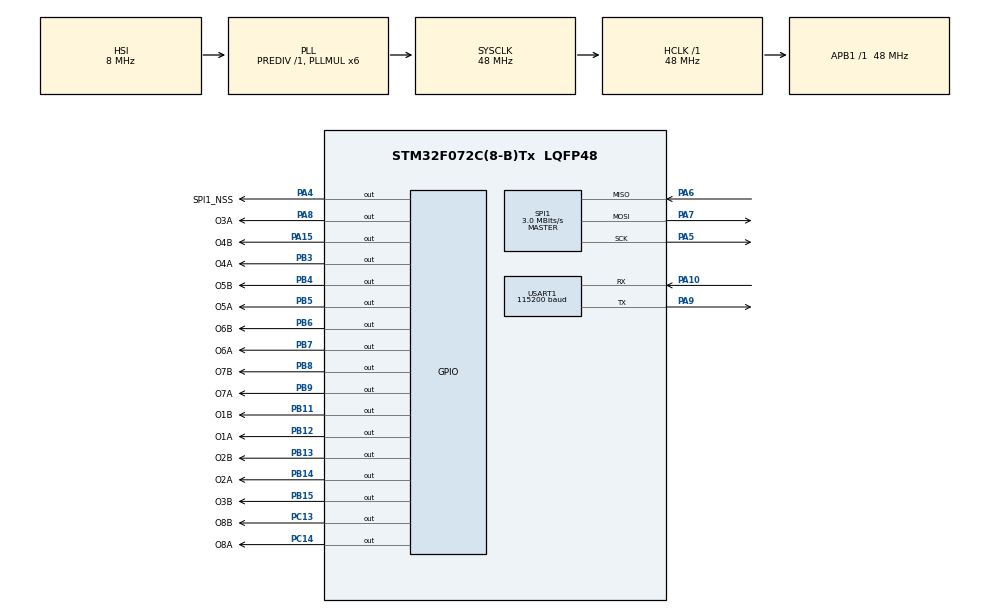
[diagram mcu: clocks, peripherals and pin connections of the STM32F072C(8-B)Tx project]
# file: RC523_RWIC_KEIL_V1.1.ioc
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Mcu.Family=STM32F0
Mcu.Name=STM32F072C(8-B)Tx
Mcu.Package=LQFP48
PA10.Mode=Asynchronous
PA10.Signal=USART1_RX
PA13.Mode=Serial_Wire
PA13.Signal=SYS_SWDIO
PA14.Mode=Serial_Wire
PA14.Signal=SYS_SWCLK
PA15.GPIO_Label=O4B
PA15.GPIO_Speed=GPIO_SPEED_FREQ_HIGH
PA15.PinState=GPIO_PIN_SET
PA15.Signal=GPIO_Output
PA4.GPIO_Label=SPI1_NSS
PA4.GPIO_Speed=GPIO_SPEED_FREQ_HIGH
PA4.PinState=GPIO_PIN_SET
PA4.Signal=GPIO_Output
PA5.Mode=Full_Duplex_Master
PA5.Signal=SPI1_SCK
PA6.Mode=Full_Duplex_Master
PA6.Signal=SPI1_MISO
PA7.Mode=Full_Duplex_Master
PA7.Signal=SPI1_MOSI
PA8.GPIO_Label=O3A
PA8.GPIO_Speed=GPIO_SPEED_FREQ_HIGH
PA8.PinState=GPIO_PIN_RESET
PA8.Signal=GPIO_Output
PA9.Mode=Asynchronous
PA9.Signal=USART1_TX
PB11.GPIO_Label=O1B
PB11.GPIO_Speed=GPIO_SPEED_FREQ_HIGH
PB11.PinState=GPIO_PIN_SET
PB11.Signal=GPIO_Output
PB12.GPIO_Label=O1A
PB12.GPIO_Speed=GPIO_SPEED_FREQ_HIGH
PB12.PinState=GPIO_PIN_RESET
PB12.Signal=GPIO_Output
PB13.GPIO_Label=O2B
PB13.GPIO_Speed=GPIO_SPEED_FREQ_HIGH
PB13.PinState=GPIO_PIN_SET
PB13.Signal=GPIO_Output
PB14.GPIO_Label=O2A
PB14.GPIO_Speed=GPIO_SPEED_FREQ_HIGH
PB14.PinState=GPIO_PIN_RESET
PB14.Signal=GPIO_Output
PB15.GPIO_Label=O3B
PB15.GPIO_Speed=GPIO_SPEED_FREQ_HIGH
PB15.PinState=GPIO_PIN_SET
PB15.Signal=GPIO_Output
PB3.GPIO_Label=O4A
PB3.GPIO_Speed=GPIO_SPEED_FREQ_HIGH
PB3.PinState=GPIO_PIN_RESET
PB3.Signal=GPIO_Output
PB4.GPIO_Label=O5B
PB4.GPIO_Speed=GPIO_SPEED_FREQ_HIGH
PB4.PinState=GPIO_PIN_SET
PB4.Signal=GPIO_Output
PB5.GPIO_Label=O5A
PB5.GPIO_Speed=GPIO_SPEED_FREQ_HIGH
PB5.Signal=GPIO_Output
PB6.GPIO_Label=O6B
PB6.GPIO_Speed=GPIO_SPEED_FREQ_HIGH
PB6.PinState=GPIO_PIN_SET
PB6.Signal=GPIO_Output
PB7.GPIO_Label=O6A
PB7.GPIO_Speed=GPIO_SPEED_FREQ_HIGH
PB7.PinState=GPIO_PIN_RESET
PB7.Signal=GPIO_Output
PB8.GPIO_Label=O7B
PB8.GPIO_Speed=GPIO_SPEED_FREQ_HIGH
PB8.PinState=GPIO_PIN_SET
PB8.Signal=GPIO_Output
PB9.GPIO_Label=O7A
PB9.GPIO_Speed=GPIO_SPEED_FREQ_HIGH
PB9.Signal=GPIO_Output
PC13.GPIO_Label=O8B
PC13.PinState=GPIO_PIN_SET
PC13.Signal=GPIO_Output
PC14-OSC32_IN.GPIO_Label=O8A
PC14-OSC32_IN.PinState=GPIO_PIN_RESET
PC14-OSC32_IN.Signal=GPIO_Output
PF0-OSC_IN.Mode=HSE-External-Oscillator
PF0-OSC_IN.Signal=RCC_OSC_IN
PF1-OSC_OUT.Mode=HSE-External-Oscillator
PF1-OSC_OUT.Signal=RCC_OSC_OUT
ProjectManager.HeapSize=0x200
ProjectManager.StackSize=0x400
ProjectManager.TargetToolchain=MDK-ARM V5.32
RCC.AHBFreq_Value=48000000
RCC.APB1Freq_Value=48000000
RCC.APB1TimFreq_Value=48000000
RCC.HCLKFreq_Value=48000000
RCC.PLLMUL=RCC_PLL_MUL6
RCC.SYSCLKFreq_VALUE=48000000
RCC.SYSCLKSource=RCC_SYSCLKSOURCE_PLLCLK
SPI1.BaudRatePrescaler=SPI_BAUDRATEPRESCALER_16
SPI1.CalculateBaudRate=3.0 MBits/s
SPI1.DataSize=SPI_DATASIZE_8BIT
SPI1.Direction=SPI_DIRECTION_2LINES
SPI1.Mode=SPI_MODE_MASTER
SPI1.VirtualType=VM_MASTER
USART1.BaudRate=115200
USART1.VirtualMode-Asynchronous=VM_ASYNC
board=custom

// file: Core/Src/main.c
/* USER CODE BEGIN Header */
/**
  ******************************************************************************
  * @file           : main.c
  * @brief          : Main program body
  ******************************************************************************
  * @attention
  *
  * Copyright (c) 2024 STMicroelectronics.
  * All rights reserved.
  *
  * This software is licensed under terms that can be found in the LICENSE file
  * in the root directory of this software component.
  * If no LICENSE file comes with this software, it is provided AS-IS.
  *
  ******************************************************************************
  */
/* USER CODE END Header */
#include "main.h"
#include "spi.h"
#include "usart.h"
#include "gpio.h"

/* USER CODE BEGIN Includes */
#include "RC523.h"
/* USER CODE END Includes */

void SystemClock_Config(void);

int main(void)
{

  /* MCU Configuration--------------------------------------------------------*/

  /* Reset of all peripherals, Initializes the Flash interface and the Systick. */
  HAL_Init();

  /* Configure the system clock */
  SystemClock_Config();

  /* Initialize all configured peripherals */
  MX_GPIO_Init();
  MX_SPI1_Init();
  MX_USART1_UART_Init();
  /* USER CODE BEGIN 2 */
  RC523_Init();
  /* USER CODE END 2 */

  /* Infinite loop */
  /* USER CODE BEGIN WHILE */
  while (1)
  {
		ScanChannlx();
		//HAL_Delay(3000);
		//HAL_Delay(1000);
    /* USER CODE END WHILE */

  }
}

void SystemClock_Config(void)
{
  RCC_OscInitTypeDef RCC_OscInitStruct = {0};
  RCC_ClkInitTypeDef RCC_ClkInitStruct = {0};
  RCC_PeriphCLKInitTypeDef PeriphClkInit = {0};

  /** Initializes the RCC Oscillators according to the specified parameters
  * in the RCC_OscInitTypeDef structure.
  */
  RCC_OscInitStruct.OscillatorType = RCC_OSCILLATORTYPE_HSI;
  RCC_OscInitStruct.HSIState = RCC_HSI_ON;
  RCC_OscInitStruct.HSICalibrationValue = RCC_HSICALIBRATION_DEFAULT;
  RCC_OscInitStruct.PLL.PLLState = RCC_PLL_ON;
  RCC_OscInitStruct.PLL.PLLSource = RCC_PLLSOURCE_HSI;
  RCC_OscInitStruct.PLL.PLLMUL = RCC_PLL_MUL6;
  RCC_OscInitStruct.PLL.PREDIV = RCC_PREDIV_DIV1;
  if (HAL_RCC_OscConfig(&RCC_OscInitStruct) != HAL_OK)
  {
    Error_Handler();
  }

  /** Initializes the CPU, AHB and APB buses clocks
  */
  RCC_ClkInitStruct.ClockType = RCC_CLOCKTYPE_HCLK|RCC_CLOCKTYPE_SYSCLK
                              |RCC_CLOCKTYPE_PCLK1;
  RCC_ClkInitStruct.SYSCLKSource = RCC_SYSCLKSOURCE_PLLCLK;
  RCC_ClkInitStruct.AHBCLKDivider = RCC_SYSCLK_DIV1;
  RCC_ClkInitStruct.APB1CLKDivider = RCC_HCLK_DIV1;

  if (HAL_RCC_ClockConfig(&RCC_ClkInitStruct, FLASH_LATENCY_1) != HAL_OK)
  {
    Error_Handler();
  }
  PeriphClkInit.PeriphClockSelection = RCC_PERIPHCLK_USART1;
  PeriphClkInit.Usart1ClockSelection = RCC_USART1CLKSOURCE_PCLK1;
  if (HAL_RCCEx_PeriphCLKConfig(&PeriphClkInit) != HAL_OK)
  {
    Error_Handler();
  }
}

void Error_Handler(void)
{
  __disable_irq();
  while (1)
  {
  }
}
